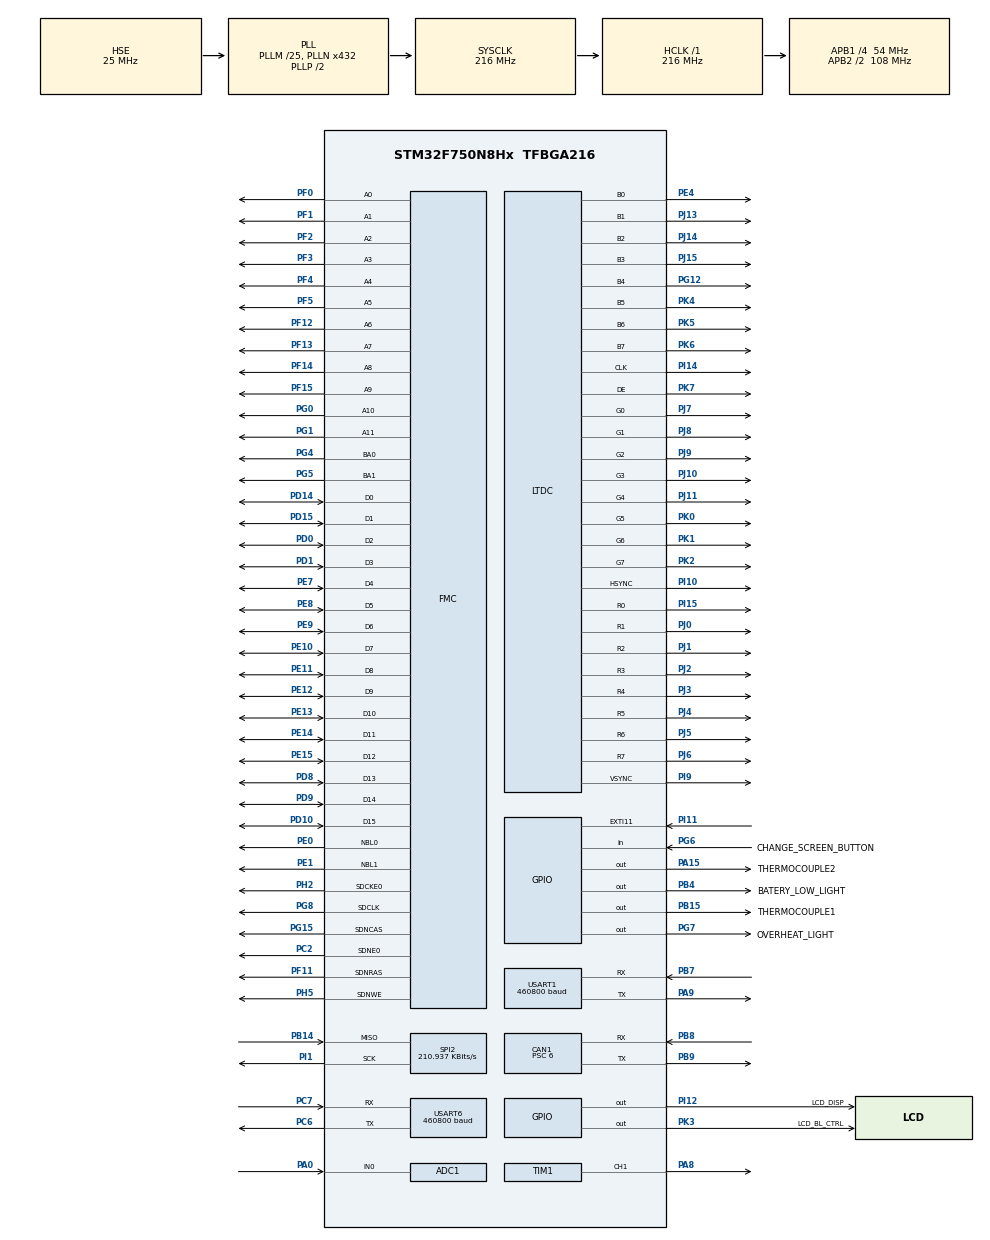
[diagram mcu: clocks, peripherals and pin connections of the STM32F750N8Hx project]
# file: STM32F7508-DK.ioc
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ADC1.Channel-0\#ChannelRegularConversion=ADC_CHANNEL_0
ADC1.NbrOfConversionFlag=1
ADC1.Rank-0\#ChannelRegularConversion=1
ADC1.SamplingTime-0\#ChannelRegularConversion=ADC_SAMPLETIME_3CYCLES
ADC1.master=1
CAN1.BS1=CAN_BS1_4TQ
CAN1.BS2=CAN_BS2_4TQ
CAN1.CalculateBaudRate=1000000
CAN1.CalculateTimeBit=1000
CAN1.CalculateTimeQuantum=111.11111111111111
CAN1.Prescaler=6
CORTEX_M7.ART_ACCLERATOR_ENABLE=1
CORTEX_M7.AccessPermission-Cortex_Memory_Protection_Unit_Region0_Settings=MPU_REGION_FULL_ACCESS
CORTEX_M7.AccessPermission-Cortex_Memory_Protection_Unit_Region1_Settings=MPU_REGION_NO_ACCESS
CORTEX_M7.AccessPermission-Cortex_Memory_Protection_Unit_Region2_Settings=MPU_REGION_FULL_ACCESS
CORTEX_M7.AccessPermission-Cortex_Memory_Protection_Unit_Region3_Settings=MPU_REGION_NO_ACCESS
CORTEX_M7.AccessPermission-Cortex_Memory_Protection_Unit_Region4_Settings=MPU_REGION_FULL_ACCESS
CORTEX_M7.AccessPermission-Cortex_Memory_Protection_Unit_Region5_Settings=MPU_REGION_FULL_ACCESS
CORTEX_M7.BaseAddress-Cortex_Memory_Protection_Unit_Region0_Settings=0x20000000
CORTEX_M7.BaseAddress-Cortex_Memory_Protection_Unit_Region1_Settings=0xC0000000
CORTEX_M7.BaseAddress-Cortex_Memory_Protection_Unit_Region2_Settings=0xC0000000
CORTEX_M7.BaseAddress-Cortex_Memory_Protection_Unit_Region3_Settings=0x90000000
CORTEX_M7.BaseAddress-Cortex_Memory_Protection_Unit_Region4_Settings=0x90000000
CORTEX_M7.BaseAddress-Cortex_Memory_Protection_Unit_Region5_Settings=0x90000000
CORTEX_M7.CPU_DCache=Enabled
CORTEX_M7.CPU_ICache=Enabled
CORTEX_M7.DisableExec-Cortex_Memory_Protection_Unit_Region0_Settings=MPU_INSTRUCTION_ACCESS_DISABLE
CORTEX_M7.DisableExec-Cortex_Memory_Protection_Unit_Region1_Settings=MPU_INSTRUCTION_ACCESS_DISABLE
CORTEX_M7.DisableExec-Cortex_Memory_Protection_Unit_Region2_Settings=MPU_INSTRUCTION_ACCESS_DISABLE
CORTEX_M7.DisableExec-Cortex_Memory_Protection_Unit_Region3_Settings=MPU_INSTRUCTION_ACCESS_DISABLE
CORTEX_M7.DisableExec-Cortex_Memory_Protection_Unit_Region4_Settings=MPU_INSTRUCTION_ACCESS_DISABLE
CORTEX_M7.Enable-Cortex_Memory_Protection_Unit_Region0_Settings=MPU_REGION_ENABLE
CORTEX_M7.Enable-Cortex_Memory_Protection_Unit_Region1_Settings=MPU_REGION_ENABLE
CORTEX_M7.Enable-Cortex_Memory_Protection_Unit_Region2_Settings=MPU_REGION_ENABLE
CORTEX_M7.Enable-Cortex_Memory_Protection_Unit_Region3_Settings=MPU_REGION_ENABLE
CORTEX_M7.Enable-Cortex_Memory_Protection_Unit_Region4_Settings=MPU_REGION_ENABLE
CORTEX_M7.Enable-Cortex_Memory_Protection_Unit_Region5_Settings=MPU_REGION_ENABLE
CORTEX_M7.IsBufferable-Cortex_Memory_Protection_Unit_Region0_Settings=MPU_ACCESS_BUFFERABLE
CORTEX_M7.IsBufferable-Cortex_Memory_Protection_Unit_Region1_Settings=MPU_ACCESS_NOT_BUFFERABLE
CORTEX_M7.IsBufferable-Cortex_Memory_Protection_Unit_Region2_Settings=MPU_ACCESS_BUFFERABLE
CORTEX_M7.IsBufferable-Cortex_Memory_Protection_Unit_Region3_Settings=MPU_ACCESS_NOT_BUFFERABLE
CORTEX_M7.IsBufferable-Cortex_Memory_Protection_Unit_Region4_Settings=MPU_ACCESS_BUFFERABLE
CORTEX_M7.IsBufferable-Cortex_Memory_Protection_Unit_Region5_Settings=MPU_ACCESS_BUFFERABLE
CORTEX_M7.IsCacheable-Cortex_Memory_Protection_Unit_Region0_Settings=MPU_ACCESS_CACHEABLE
CORTEX_M7.IsCacheable-Cortex_Memory_Protection_Unit_Region1_Settings=MPU_ACCESS_NOT_CACHEABLE
CORTEX_M7.IsCacheable-Cortex_Memory_Protection_Unit_Region2_Settings=MPU_ACCESS_CACHEABLE
CORTEX_M7.IsCacheable-Cortex_Memory_Protection_Unit_Region3_Settings=MPU_ACCESS_NOT_CACHEABLE
CORTEX_M7.IsCacheable-Cortex_Memory_Protection_Unit_Region4_Settings=MPU_ACCESS_CACHEABLE
CORTEX_M7.IsCacheable-Cortex_Memory_Protection_Unit_Region5_Settings=MPU_ACCESS_CACHEABLE
CORTEX_M7.MPU_Control=MPU_PRIVILEGED_DEFAULT
CORTEX_M7.PREFETCH_ENABLE=1
CORTEX_M7.Size-Cortex_Memory_Protection_Unit_Region0_Settings=MPU_REGION_SIZE_512KB
CORTEX_M7.Size-Cortex_Memory_Protection_Unit_Region1_Settings=MPU_REGION_SIZE_512MB
CORTEX_M7.Size-Cortex_Memory_Protection_Unit_Region2_Settings=MPU_REGION_SIZE_8MB
CORTEX_M7.Size-Cortex_Memory_Protection_Unit_Region3_Settings=MPU_REGION_SIZE_512MB
CORTEX_M7.Size-Cortex_Memory_Protection_Unit_Region4_Settings=MPU_REGION_SIZE_16MB
CORTEX_M7.Size-Cortex_Memory_Protection_Unit_Region5_Settings=MPU_REGION_SIZE_1MB
DMA2D.ColorMode=DMA2D_OUTPUT_ARGB8888
Dma.Request0=TIM1_CH1
Dma.Request1=SPI2_RX
Dma.Request2=USART6_RX
Dma.SPI2_RX.1.Direction=DMA_PERIPH_TO_MEMORY
Dma.SPI2_RX.1.FIFOMode=DMA_FIFOMODE_DISABLE
Dma.SPI2_RX.1.Instance=DMA1_Stream3
Dma.SPI2_RX.1.MemDataAlignment=DMA_MDATAALIGN_BYTE
Dma.SPI2_RX.1.MemInc=DMA_MINC_ENABLE
Dma.SPI2_RX.1.Mode=DMA_NORMAL
Dma.SPI2_RX.1.PeriphDataAlignment=DMA_PDATAALIGN_BYTE
Dma.SPI2_RX.1.PeriphInc=DMA_PINC_DISABLE
Dma.SPI2_RX.1.Priority=DMA_PRIORITY_LOW
Dma.TIM1_CH1.0.Direction=DMA_MEMORY_TO_PERIPH
Dma.TIM1_CH1.0.FIFOMode=DMA_FIFOMODE_DISABLE
Dma.TIM1_CH1.0.Instance=DMA2_Stream1
Dma.TIM1_CH1.0.MemDataAlignment=DMA_MDATAALIGN_HALFWORD
Dma.TIM1_CH1.0.MemInc=DMA_MINC_ENABLE
Dma.TIM1_CH1.0.Mode=DMA_NORMAL
Dma.TIM1_CH1.0.PeriphDataAlignment=DMA_PDATAALIGN_HALFWORD
Dma.TIM1_CH1.0.PeriphInc=DMA_PINC_DISABLE
Dma.TIM1_CH1.0.Priority=DMA_PRIORITY_LOW
Dma.USART6_RX.2.Direction=DMA_PERIPH_TO_MEMORY
Dma.USART6_RX.2.FIFOMode=DMA_FIFOMODE_DISABLE
Dma.USART6_RX.2.Instance=DMA2_Stream2
Dma.USART6_RX.2.MemDataAlignment=DMA_MDATAALIGN_BYTE
Dma.USART6_RX.2.MemInc=DMA_MINC_ENABLE
Dma.USART6_RX.2.Mode=DMA_NORMAL
Dma.USART6_RX.2.PeriphDataAlignment=DMA_PDATAALIGN_BYTE
Dma.USART6_RX.2.PeriphInc=DMA_PINC_DISABLE
Dma.USART6_RX.2.Priority=DMA_PRIORITY_LOW
FREERTOS.INCLUDE_eTaskGetState=1
FREERTOS.INCLUDE_pcTaskGetTaskName=0
FREERTOS.INCLUDE_uxTaskGetStackHighWaterMark=1
FREERTOS.INCLUDE_vTaskCleanUpResources=0
FREERTOS.INCLUDE_vTaskDelayUntil=1
FREERTOS.INCLUDE_xQueueGetMutexHolder=1
FREERTOS.INCLUDE_xSemaphoreGetMutexHolder=1
FREERTOS.INCLUDE_xTimerPendFunctionCall=1
FREERTOS.MEMORY_ALLOCATION=2
FREERTOS.Queues01=buttonQueue,4,uint8_t,0,Dynamic,NULL,NULL;shifterQueue,8,uint8_t,0,Dynamic,NULL,NULL
FREERTOS.Tasks01=defaultTask,24,128,StartDefaultTask,Default,NULL,Dynamic,NULL,NULL;TouchGFXTask,24,8192,TouchGFX_Task,As external,NULL,Dynamic,NULL,NULL;rpmTask,8,128,StartRPMTask,Default,NULL,Dynamic,NULL,NULL;egtTask,8,128,StartEGTTask,Default,NULL,Dynamic,NULL,NULL;shifterTask,8,128,StartShifterTask,Default,NULL,Dynamic,NULL,NULL;gpsTask,8,128,StartGPSTask,Default,NULL,Dynamic,NULL,NULL;debounceTask,8,128,StartDebounce,Default,NULL,Dynamic,NULL,NULL
FREERTOS.configTOTAL_HEAP_SIZE=65536
FREERTOS.configUSE_APPLICATION_TASK_TAG=1
FREERTOS.configUSE_COUNTING_SEMAPHORES=1
FREERTOS.configUSE_IDLE_HOOK=1
FREERTOS.configUSE_RECURSIVE_MUTEXES=1
FREERTOS.configUSE_TIMERS=1
FREERTOS.configUSE_TRACE_FACILITY=1
LTDC.ActiveH=272
LTDC.ActiveW=480
LTDC.Alpha_L0=255
LTDC.HBP=13
LTDC.HFP=32
LTDC.HSync=41
LTDC.ImageHeight_L0=272
LTDC.ImageWidth_L0=480
LTDC.Layers=0
LTDC.PixelFormat_L0=LTDC_PIXEL_FORMAT_RGB565
LTDC.VSync=10
LTDC.WindowX1_L0=480
LTDC.WindowY1_L0=272
Mcu.Family=STM32F7
Mcu.Name=STM32F750N8Hx
Mcu.Package=TFBGA216
NVIC.CAN1_RX0_IRQn=true\:5\:0\:false\:false\:true\:true\:true\:true\:true
NVIC.CAN1_TX_IRQn=true\:5\:0\:false\:false\:true\:true\:true\:true\:true
NVIC.DMA1_Stream3_IRQn=true\:5\:0\:false\:false\:true\:true\:false\:true\:true
NVIC.DMA2D_IRQn=true\:5\:0\:true\:false\:true\:false\:true\:true\:true
NVIC.DMA2_Stream1_IRQn=true\:5\:0\:false\:false\:true\:true\:false\:true\:true
NVIC.DMA2_Stream2_IRQn=true\:5\:0\:false\:false\:true\:true\:false\:true\:true
NVIC.EXTI15_10_IRQn=true\:5\:0\:false\:false\:true\:true\:true\:true\:true
NVIC.LTDC_IRQn=true\:5\:0\:true\:false\:true\:false\:true\:true\:true
NVIC.PriorityGroup=NVIC_PRIORITYGROUP_4
NVIC.TIM2_IRQn=true\:5\:0\:false\:false\:true\:true\:true\:true\:true
NVIC.TIM6_DAC_IRQn=true\:0\:0\:false\:false\:true\:false\:false\:true\:true
NVIC.TimeBase=TIM6_DAC_IRQn
NVIC.TimeBaseIP=TIM6
NVIC.USART6_IRQn=true\:5\:0\:false\:false\:true\:true\:true\:true\:true
PA0/WKUP.Signal=ADCx_IN0
PA15.GPIO_Label=THERMOCOUPLE2
PA15.Signal=GPIO_Output
PA8.Signal=S_TIM1_CH1
PA9.Mode=Asynchronous
PA9.Signal=USART1_TX
PB14.Mode=RX_Only_Simplex_Unidirect_Master
PB14.Signal=SPI2_MISO
PB15.GPIO_Label=THERMOCOUPLE1
PB15.Signal=GPIO_Output
PB4.GPIO_Label=BATERY_LOW_LIGHT
PB4.Signal=GPIO_Output
PB7.Mode=Asynchronous
PB7.Signal=USART1_RX
PB8.Mode=CAN_Activate
PB8.Signal=CAN1_RX
PB9.Mode=CAN_Activate
PB9.Signal=CAN1_TX
PC2.Mode=SdramChipSelect1_1
PC2.Signal=FMC_SDNE0
PC6.Mode=Asynchronous
PC6.Signal=USART6_TX
PC7.Mode=Asynchronous
PC7.Signal=USART6_RX
PD0.Signal=FMC_D2_DA2
PD1.Signal=FMC_D3_DA3
PD10.Signal=FMC_D15_DA15
PD14.Signal=FMC_D0_DA0
PD15.Signal=FMC_D1_DA1
PD8.Signal=FMC_D13_DA13
PD9.Signal=FMC_D14_DA14
PE0.Signal=FMC_NBL0
PE1.Signal=FMC_NBL1
PE10.Signal=FMC_D7_DA7
PE11.Signal=FMC_D8_DA8
PE12.Signal=FMC_D9_DA9
PE13.Signal=FMC_D10_DA10
PE14.Signal=FMC_D11_DA11
PE15.Signal=FMC_D12_DA12
PE4.GPIO_Speed=GPIO_SPEED_FREQ_HIGH
PE4.Mode=RGB888
PE4.Signal=LTDC_B0
PE7.Signal=FMC_D4_DA4
PE8.Signal=FMC_D5_DA5
PE9.Signal=FMC_D6_DA6
PF0.Signal=FMC_A0
PF1.Signal=FMC_A1
PF11.Signal=FMC_SDNRAS
PF12.Signal=FMC_A6
PF13.Signal=FMC_A7
PF14.Signal=FMC_A8
PF15.Signal=FMC_A9
PF2.Signal=FMC_A2
PF3.Signal=FMC_A3
PF4.Signal=FMC_A4
PF5.Signal=FMC_A5
PG0.Signal=FMC_A10
PG1.Signal=FMC_A11
PG12.GPIO_Speed=GPIO_SPEED_FREQ_HIGH
PG12.Mode=RGB888
PG12.Signal=LTDC_B4
PG15.Signal=FMC_SDNCAS
PG4.Signal=FMC_A14_BA0
PG5.Signal=FMC_A15_BA1
PG6.GPIO_Label=CHANGE_SCREEN_BUTTON
PG6.GPIO_PuPd=GPIO_PULLUP
PG6.Signal=GPIO_Input
PG7.GPIO_Label=OVERHEAT_LIGHT
PG7.Signal=GPIO_Output
PG8.Signal=FMC_SDCLK
PH0/OSC_IN.Mode=HSE-External-Oscillator
PH0/OSC_IN.Signal=RCC_OSC_IN
PH1/OSC_OUT.Mode=HSE-External-Oscillator
PH1/OSC_OUT.Signal=RCC_OSC_OUT
PH2.Mode=SdramChipSelect1_1
PH2.Signal=FMC_SDCKE0
PH5.Signal=FMC_SDNWE
PI1.Mode=RX_Only_Simplex_Unidirect_Master
PI1.Signal=SPI2_SCK
PI10.GPIO_Speed=GPIO_SPEED_FREQ_HIGH
PI10.Mode=RGB888
PI10.Signal=LTDC_HSYNC
PI11.GPIO_PuPd=GPIO_PULLDOWN
PI11.Signal=GPXTI11
PI12.GPIO_Label=LCD_DISP
PI12.Signal=GPIO_Output
PI14.GPIO_Speed=GPIO_SPEED_FREQ_HIGH
PI14.Mode=RGB888
PI14.Signal=LTDC_CLK
PI15.GPIO_Speed=GPIO_SPEED_FREQ_HIGH
PI15.Mode=RGB888
PI15.Signal=LTDC_R0
PI9.GPIO_Speed=GPIO_SPEED_FREQ_HIGH
PI9.Mode=RGB888
PI9.Signal=LTDC_VSYNC
PJ0.GPIO_Speed=GPIO_SPEED_FREQ_HIGH
PJ0.Mode=RGB888
PJ0.Signal=LTDC_R1
PJ1.GPIO_Speed=GPIO_SPEED_FREQ_HIGH
PJ1.Mode=RGB888
PJ1.Signal=LTDC_R2
PJ10.GPIO_Speed=GPIO_SPEED_FREQ_HIGH
PJ10.Mode=RGB888
PJ10.Signal=LTDC_G3
PJ11.GPIO_Speed=GPIO_SPEED_FREQ_HIGH
PJ11.Mode=RGB888
PJ11.Signal=LTDC_G4
PJ13.GPIO_Speed=GPIO_SPEED_FREQ_HIGH
PJ13.Mode=RGB888
PJ13.Signal=LTDC_B1
PJ14.GPIO_Speed=GPIO_SPEED_FREQ_HIGH
PJ14.Mode=RGB888
PJ14.Signal=LTDC_B2
PJ15.GPIO_Speed=GPIO_SPEED_FREQ_HIGH
PJ15.Mode=RGB888
PJ15.Signal=LTDC_B3
PJ2.GPIO_Speed=GPIO_SPEED_FREQ_HIGH
PJ2.Mode=RGB888
PJ2.Signal=LTDC_R3
PJ3.GPIO_Speed=GPIO_SPEED_FREQ_HIGH
PJ3.Mode=RGB888
PJ3.Signal=LTDC_R4
PJ4.GPIO_Speed=GPIO_SPEED_FREQ_HIGH
PJ4.Mode=RGB888
PJ4.Signal=LTDC_R5
PJ5.GPIO_Speed=GPIO_SPEED_FREQ_HIGH
PJ5.Mode=RGB888
PJ5.Signal=LTDC_R6
PJ6.GPIO_Speed=GPIO_SPEED_FREQ_HIGH
PJ6.Mode=RGB888
PJ6.Signal=LTDC_R7
PJ7.GPIO_Speed=GPIO_SPEED_FREQ_HIGH
PJ7.Mode=RGB888
PJ7.Signal=LTDC_G0
PJ8.GPIO_Speed=GPIO_SPEED_FREQ_HIGH
PJ8.Mode=RGB888
PJ8.Signal=LTDC_G1
PJ9.GPIO_Speed=GPIO_SPEED_FREQ_HIGH
PJ9.Mode=RGB888
PJ9.Signal=LTDC_G2
PK0.GPIO_Speed=GPIO_SPEED_FREQ_HIGH
PK0.Mode=RGB888
PK0.Signal=LTDC_G5
PK1.GPIO_Speed=GPIO_SPEED_FREQ_HIGH
PK1.Mode=RGB888
PK1.Signal=LTDC_G6
PK2.GPIO_Speed=GPIO_SPEED_FREQ_HIGH
PK2.Mode=RGB888
PK2.Signal=LTDC_G7
PK3.GPIO_Label=LCD_BL_CTRL
PK3.Signal=GPIO_Output
PK4.GPIO_Speed=GPIO_SPEED_FREQ_HIGH
PK4.Mode=RGB888
PK4.Signal=LTDC_B5
PK5.GPIO_Speed=GPIO_SPEED_FREQ_HIGH
PK5.Mode=RGB888
PK5.Signal=LTDC_B6
PK6.GPIO_Speed=GPIO_SPEED_FREQ_HIGH
PK6.Mode=RGB888
PK6.Signal=LTDC_B7
PK7.GPIO_Speed=GPIO_SPEED_FREQ_HIGH
PK7.Mode=RGB888
PK7.Signal=LTDC_DE
ProjectManager.HeapSize=0x1000
ProjectManager.StackSize=0x1000
ProjectManager.TargetToolchain=STM32CubeIDE
RCC.AHBFreq_Value=216000000
RCC.APB1CLKDivider=RCC_HCLK_DIV4
RCC.APB1Freq_Value=54000000
RCC.APB1TimFreq_Value=108000000
RCC.APB2CLKDivider=RCC_HCLK_DIV2
RCC.APB2Freq_Value=108000000
RCC.APB2TimFreq_Value=216000000
RCC.CortexFreq_Value=216000000
RCC.HCLKFreq_Value=216000000
RCC.HSE_VALUE=25000000
RCC.HSI_VALUE=16000000
RCC.LSE_VALUE=32768
RCC.PLLM=25
RCC.PLLN=432
RCC.PLLSAIN=100
RCC.PLLSourceVirtual=RCC_PLLSOURCE_HSE
RCC.SYSCLKFreq_VALUE=216000000
RCC.SYSCLKSource=RCC_SYSCLKSOURCE_PLLCLK
RCC.USBFreq_Value=216000000
RCC.VCOOutputFreq_Value=432000000
SH.ADCx_IN0.0=ADC1_IN0,IN0
SH.FMC_A0.0=FMC_A0,12b-sda1
SH.FMC_A1.0=FMC_A1,12b-sda1
SH.FMC_A10.0=FMC_A10,12b-sda1
SH.FMC_A11.0=FMC_A11,12b-sda1
SH.FMC_A14_BA0.0=FMC_BA0,FourSdramBanks1
SH.FMC_A15_BA1.0=FMC_BA1,FourSdramBanks1
SH.FMC_A2.0=FMC_A2,12b-sda1
SH.FMC_A3.0=FMC_A3,12b-sda1
SH.FMC_A4.0=FMC_A4,12b-sda1
SH.FMC_A5.0=FMC_A5,12b-sda1
SH.FMC_A6.0=FMC_A6,12b-sda1
SH.FMC_A7.0=FMC_A7,12b-sda1
SH.FMC_A8.0=FMC_A8,12b-sda1
SH.FMC_A9.0=FMC_A9,12b-sda1
SH.FMC_D0_DA0.0=FMC_D0,sd-16b-d1
SH.FMC_D10_DA10.0=FMC_D10,sd-16b-d1
SH.FMC_D11_DA11.0=FMC_D11,sd-16b-d1
SH.FMC_D12_DA12.0=FMC_D12,sd-16b-d1
SH.FMC_D13_DA13.0=FMC_D13,sd-16b-d1
SH.FMC_D14_DA14.0=FMC_D14,sd-16b-d1
SH.FMC_D15_DA15.0=FMC_D15,sd-16b-d1
SH.FMC_D1_DA1.0=FMC_D1,sd-16b-d1
SH.FMC_D2_DA2.0=FMC_D2,sd-16b-d1
SH.FMC_D3_DA3.0=FMC_D3,sd-16b-d1
SH.FMC_D4_DA4.0=FMC_D4,sd-16b-d1
SH.FMC_D5_DA5.0=FMC_D5,sd-16b-d1
SH.FMC_D6_DA6.0=FMC_D6,sd-16b-d1
SH.FMC_D7_DA7.0=FMC_D7,sd-16b-d1
SH.FMC_D8_DA8.0=FMC_D8,sd-16b-d1
SH.FMC_D9_DA9.0=FMC_D9,sd-16b-d1
SH.FMC_NBL0.0=FMC_NBL0,Sd2ByteEnable1
SH.FMC_NBL1.0=FMC_NBL1,Sd2ByteEnable1
SH.FMC_SDCLK.0=FMC_SDCLK,12b-sda1
SH.FMC_SDNCAS.0=FMC_SDNCAS,12b-sda1
SH.FMC_SDNRAS.0=FMC_SDNRAS,12b-sda1
SH.FMC_SDNWE.0=FMC_SDNWE,12b-sda1
SH.S_TIM1_CH1.0=TIM1_CH1,PWM Generation1 CH1
SPI2.BaudRatePrescaler=SPI_BAUDRATEPRESCALER_256
SPI2.CalculateBaudRate=210.937 KBits/s
SPI2.DataSize=SPI_DATASIZE_8BIT
SPI2.Direction=SPI_DIRECTION_2LINES_RXONLY
SPI2.Mode=SPI_MODE_MASTER
SPI2.VirtualType=VM_MASTER
STMicroelectronics.X-CUBE-TOUCHGFX.4.23.0.ApplicationCcGraphicsJjApplication=TouchGFXOoGenerator
STMicroelectronics.X-CUBE-TOUCHGFX.4.23.0.tgfx_address1=0xC0000000
STMicroelectronics.X-CUBE-TOUCHGFX.4.23.0.tgfx_address2=0xC003FC00
STMicroelectronics.X-CUBE-TOUCHGFX.4.23.0.tgfx_buffering_strategy=Double
STMicroelectronics.X-CUBE-TOUCHGFX.4.23.0.tgfx_display_interface=disp_ltdc
STMicroelectronics.X-CUBE-TOUCHGFX.4.23.0.tgfx_hardware_accelerator=dma_2d
STMicroelectronics.X-CUBE-TOUCHGFX.4.23.0.tgfx_location=By Address
STMicroelectronics.X-CUBE-TOUCHGFX.4.23.0.tgfx_vector_rendering=Enabled
STMicroelectronics.X-CUBE-TOUCHGFX.4.23.0.tgfx_vsync=vsync_ltdc
TIM1.AutoReloadPreload=TIM_AUTORELOAD_PRELOAD_ENABLE
TIM1.Channel-PWM\ Generation1\ CH1=TIM_CHANNEL_1
TIM1.Period=270
TIM2.AutoReloadPreload=TIM_AUTORELOAD_PRELOAD_ENABLE
TIM2.Period=30000
TIM2.Prescaler=1000
USART1.BaudRate=460800
USART1.VirtualMode-Asynchronous=VM_ASYNC
USART6.BaudRate=460800
USART6.VirtualMode-Asynchronous=VM_ASYNC
VP_CRC_VS_CRC.Mode=CRC_Activate
VP_DMA2D_VS_DMA2D.Mode=DMA2D_Activate
VP_FREERTOS_VS_CMSIS_V2.Mode=CMSIS_V2
VP_STMicroelectronics.X-CUBE-TOUCHGFX_VS_GraphicsJjApplication_4.23.0.Mode=GraphicsJjApplication
VP_SYS_VS_tim6.Mode=TIM6
VP_TIM1_VS_ClockSourceINT.Mode=Internal
VP_TIM2_VS_ClockSourceINT.Mode=Internal
board=custom

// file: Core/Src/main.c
/* USER CODE BEGIN Header */
/**
  ******************************************************************************
  * @file           : main.c
  * @brief          : Main program body
  ******************************************************************************
  * @attention
  *
  * <h2><center>&copy; Copyright (c) 2020 STMicroelectronics.
  * All rights reserved.</center></h2>
  *
  * This software component is licensed by ST under Ultimate Liberty license
  * SLA0044, the "License"; You may not use this file except in compliance with
  * the License. You may obtain a copy of the License at:
  *                             www.st.com/SLA0044
  *
  ******************************************************************************
  */
/* USER CODE END Header */
#include "main.h"
#include "cmsis_os.h"
#include "adc.h"
#include "can.h"
#include "crc.h"
#include "dma.h"
#include "dma2d.h"
#include "ltdc.h"
#include "spi.h"
#include "tim.h"
#include "usart.h"
#include "gpio.h"
#include "fmc.h"
#include "app_touchgfx.h"

/* USER CODE BEGIN Includes */
#include "stm32f7508_discovery_sdram.h"
/* USER CODE END Includes */

void SystemClock_Config(void);
static void MPU_Config(void);
void MX_FREERTOS_Init(void);

int main(void)
{

  /* MPU Configuration--------------------------------------------------------*/
  MPU_Config();

  /* Enable I-Cache---------------------------------------------------------*/
  SCB_EnableICache();

  /* Enable D-Cache---------------------------------------------------------*/
  SCB_EnableDCache();

  /* MCU Configuration--------------------------------------------------------*/

  /* Reset of all peripherals, Initializes the Flash interface and the Systick. */
  HAL_Init();

  /* Configure the system clock */
  SystemClock_Config();

  /* Initialize all configured peripherals */
  MX_GPIO_Init();
  MX_DMA_Init();
  MX_DMA2D_Init();
  MX_FMC_Init();
  MX_LTDC_Init();
  MX_USART1_UART_Init();
  MX_CAN1_Init();
  MX_TIM1_Init();
  MX_CRC_Init();
  MX_TIM2_Init();
  MX_SPI2_Init();
  MX_ADC1_Init();
  MX_USART6_UART_Init();
  MX_TouchGFX_Init();
  /* Call PreOsInit function */
  MX_TouchGFX_PreOSInit();
  /* USER CODE BEGIN 2 */
  HAL_CAN_Start(&hcan1);
  HAL_CAN_ActivateNotification(&hcan1, CAN_IT_RX_FIFO0_MSG_PENDING);
  HAL_CAN_ActivateNotification(&hcan1, CAN_IT_TX_MAILBOX_EMPTY);

  /* USER CODE END 2 */

  /* Init scheduler */
  osKernelInitialize();  /* Call init function for freertos objects (in freertos.c) */
  MX_FREERTOS_Init();

  /* Start scheduler */
  osKernelStart();
  /* We should never get here as control is now taken by the scheduler */
  /* Infinite loop */
  while (1)
  {

  }
}

void SystemClock_Config(void)
{
  RCC_OscInitTypeDef RCC_OscInitStruct = {0};
  RCC_ClkInitTypeDef RCC_ClkInitStruct = {0};

  /** Configure the main internal regulator output voltage
  */
  __HAL_RCC_PWR_CLK_ENABLE();
  __HAL_PWR_VOLTAGESCALING_CONFIG(PWR_REGULATOR_VOLTAGE_SCALE1);

  /** Initializes the RCC Oscillators according to the specified parameters
  * in the RCC_OscInitTypeDef structure.
  */
  RCC_OscInitStruct.OscillatorType = RCC_OSCILLATORTYPE_HSE;
  RCC_OscInitStruct.HSEState = RCC_HSE_ON;
  RCC_OscInitStruct.PLL.PLLState = RCC_PLL_ON;
  RCC_OscInitStruct.PLL.PLLSource = RCC_PLLSOURCE_HSE;
  RCC_OscInitStruct.PLL.PLLM = 25;
  RCC_OscInitStruct.PLL.PLLN = 432;
  RCC_OscInitStruct.PLL.PLLP = RCC_PLLP_DIV2;
  RCC_OscInitStruct.PLL.PLLQ = 2;
  if (HAL_RCC_OscConfig(&RCC_OscInitStruct) != HAL_OK)
  {
    Error_Handler();
  }

  /** Activate the Over-Drive mode
  */
  if (HAL_PWREx_EnableOverDrive() != HAL_OK)
  {
    Error_Handler();
  }

  /** Initializes the CPU, AHB and APB buses clocks
  */
  RCC_ClkInitStruct.ClockType = RCC_CLOCKTYPE_HCLK|RCC_CLOCKTYPE_SYSCLK
                              |RCC_CLOCKTYPE_PCLK1|RCC_CLOCKTYPE_PCLK2;
  RCC_ClkInitStruct.SYSCLKSource = RCC_SYSCLKSOURCE_PLLCLK;
  RCC_ClkInitStruct.AHBCLKDivider = RCC_SYSCLK_DIV1;
  RCC_ClkInitStruct.APB1CLKDivider = RCC_HCLK_DIV4;
  RCC_ClkInitStruct.APB2CLKDivider = RCC_HCLK_DIV2;

  if (HAL_RCC_ClockConfig(&RCC_ClkInitStruct, FLASH_LATENCY_7) != HAL_OK)
  {
    Error_Handler();
  }
}

/* MPU Configuration */

void MPU_Config(void)
{
  MPU_Region_InitTypeDef MPU_InitStruct = {0};

  /* Disables the MPU */
  HAL_MPU_Disable();

  /** Initializes and configures the Region and the memory to be protected
  */
  MPU_InitStruct.Enable = MPU_REGION_ENABLE;
  MPU_InitStruct.Number = MPU_REGION_NUMBER0;
  MPU_InitStruct.BaseAddress = 0x20000000;
  MPU_InitStruct.Size = MPU_REGION_SIZE_512KB;
  MPU_InitStruct.SubRegionDisable = 0x0;
  MPU_InitStruct.TypeExtField = MPU_TEX_LEVEL0;
  MPU_InitStruct.AccessPermission = MPU_REGION_FULL_ACCESS;
  MPU_InitStruct.DisableExec = MPU_INSTRUCTION_ACCESS_DISABLE;
  MPU_InitStruct.IsShareable = MPU_ACCESS_NOT_SHAREABLE;
  MPU_InitStruct.IsCacheable = MPU_ACCESS_CACHEABLE;
  MPU_InitStruct.IsBufferable = MPU_ACCESS_BUFFERABLE;

  HAL_MPU_ConfigRegion(&MPU_InitStruct);

  /** Initializes and configures the Region and the memory to be protected
  */
  MPU_InitStruct.Number = MPU_REGION_NUMBER1;
  MPU_InitStruct.BaseAddress = 0xC0000000;
  MPU_InitStruct.Size = MPU_REGION_SIZE_512MB;
  MPU_InitStruct.AccessPermission = MPU_REGION_NO_ACCESS;
  MPU_InitStruct.IsCacheable = MPU_ACCESS_NOT_CACHEABLE;
  MPU_InitStruct.IsBufferable = MPU_ACCESS_NOT_BUFFERABLE;

  HAL_MPU_ConfigRegion(&MPU_InitStruct);

  /** Initializes and configures the Region and the memory to be protected
  */
  MPU_InitStruct.Number = MPU_REGION_NUMBER2;
  MPU_InitStruct.Size = MPU_REGION_SIZE_8MB;
  MPU_InitStruct.AccessPermission = MPU_REGION_FULL_ACCESS;
  MPU_InitStruct.IsCacheable = MPU_ACCESS_CACHEABLE;
  MPU_InitStruct.IsBufferable = MPU_ACCESS_BUFFERABLE;

  HAL_MPU_ConfigRegion(&MPU_InitStruct);

  /** Initializes and configures the Region and the memory to be protected
  */
  MPU_InitStruct.Number = MPU_REGION_NUMBER3;
  MPU_InitStruct.BaseAddress = 0x90000000;
  MPU_InitStruct.Size = MPU_REGION_SIZE_512MB;
  MPU_InitStruct.AccessPermission = MPU_REGION_NO_ACCESS;
  MPU_InitStruct.IsCacheable = MPU_ACCESS_NOT_CACHEABLE;
  MPU_InitStruct.IsBufferable = MPU_ACCESS_NOT_BUFFERABLE;

  HAL_MPU_ConfigRegion(&MPU_InitStruct);

  /** Initializes and configures the Region and the memory to be protected
  */
  MPU_InitStruct.Number = MPU_REGION_NUMBER4;
  MPU_InitStruct.Size = MPU_REGION_SIZE_16MB;
  MPU_InitStruct.AccessPermission = MPU_REGION_FULL_ACCESS;
  MPU_InitStruct.IsCacheable = MPU_ACCESS_CACHEABLE;
  MPU_InitStruct.IsBufferable = MPU_ACCESS_BUFFERABLE;

  HAL_MPU_ConfigRegion(&MPU_InitStruct);

  /** Initializes and configures the Region and the memory to be protected
  */
  MPU_InitStruct.Number = MPU_REGION_NUMBER5;
  MPU_InitStruct.Size = MPU_REGION_SIZE_1MB;
  MPU_InitStruct.DisableExec = MPU_INSTRUCTION_ACCESS_ENABLE;

  HAL_MPU_ConfigRegion(&MPU_InitStruct);
  /* Enables the MPU */
  HAL_MPU_Enable(MPU_PRIVILEGED_DEFAULT);

}

void HAL_TIM_PeriodElapsedCallback(TIM_HandleTypeDef *htim)
{
  if (htim->Instance == TIM6) {
    HAL_IncTick();
  }
}

void Error_Handler(void)
{
  /* USER CODE BEGIN Error_Handler_Debug */
  /* User can add his own implementation to report the HAL error return state */
  while(1);
  /* USER CODE END Error_Handler_Debug */
}

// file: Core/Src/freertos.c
/* USER CODE BEGIN Header */
/**
  ******************************************************************************
  * File Name          : freertos.c
  * Description        : Code for freertos applications
  ******************************************************************************
  * @attention
  *
  * <h2><center>&copy; Copyright (c) 2020 STMicroelectronics.
  * All rights reserved.</center></h2>
  *
  * This software component is licensed by ST under Ultimate Liberty license
  * SLA0044, the "License"; You may not use this file except in compliance with
  * the License. You may obtain a copy of the License at:
  *                             www.st.com/SLA0044
  *
  ******************************************************************************
  */
/* USER CODE END Header */

#include "FreeRTOS.h"
#include "task.h"
#include "main.h"
#include "cmsis_os.h"

/* USER CODE BEGIN Includes */
#include "can.h"
#include "gpio.h"
#include "spi.h"
#include "adc.h"
#include "usart.h"
#include "gps.h"
/* USER CODE END Includes */

/* USER CODE BEGIN PD */
#define ADCSHIFTUP 3000
#define ADCSHIFTDOWN 1700
/* USER CODE END PD */

/* USER CODE BEGIN Variables */
uint32_t TxMailbox;
uint32_t lapTimeMilliSeconds;
gpsData_t *gpsData_r;
extern uint16_t rpm;
extern CAN_TxHeaderTypeDef TxHeader;
extern uint16_t egt3;
extern uint16_t egt4;
extern uint8_t gpsData[UARTBUFFERLENGTH];
extern uint8_t neutralSwitch;

/* USER CODE END Variables */
/* Definitions for defaultTask */
osThreadId_t defaultTaskHandle;
const osThreadAttr_t defaultTask_attributes = {
  .name = "defaultTask",
  .stack_size = 256 * 4,
  .priority = (osPriority_t) osPriorityNormal,
};
/* Definitions for TouchGFXTask */
osThreadId_t TouchGFXTaskHandle;
const osThreadAttr_t TouchGFXTask_attributes = {
  .name = "TouchGFXTask",
  .stack_size = 8192 * 4,
  .priority = (osPriority_t) osPriorityNormal,
};
/* Definitions for rpmTask */
osThreadId_t rpmTaskHandle;
const osThreadAttr_t rpmTask_attributes = {
  .name = "rpmTask",
  .stack_size = 256 * 4,
  .priority = (osPriority_t) osPriorityLow,
};
/* Definitions for egtTask */
osThreadId_t egtTaskHandle;
const osThreadAttr_t egtTask_attributes = {
  .name = "egtTask",
  .stack_size = 256 * 4,
  .priority = (osPriority_t) osPriorityLow,
};
/* Definitions for shifterTask */
osThreadId_t shifterTaskHandle;
const osThreadAttr_t shifterTask_attributes = {
  .name = "shifterTask",
  .stack_size = 256 * 4,
  .priority = (osPriority_t) osPriorityLow,
};
/* Definitions for gpsTask */
osThreadId_t gpsTaskHandle;
const osThreadAttr_t gpsTask_attributes = {
  .name = "gpsTask",
  .stack_size = 256 * 4,
  .priority = (osPriority_t) osPriorityNormal,
};
/* Definitions for debounceTask */
osThreadId_t debounceTaskHandle;
const osThreadAttr_t debounceTask_attributes = {
  .name = "debounceTask",
  .stack_size = 256 * 4,
  .priority = (osPriority_t) osPriorityLow,
};
/* Definitions for buttonQueue */
osMessageQueueId_t buttonQueueHandle;
const osMessageQueueAttr_t buttonQueue_attributes = {
  .name = "buttonQueue"
};
/* Definitions for shifterQueue */
osMessageQueueId_t shifterQueueHandle;
const osMessageQueueAttr_t shifterQueue_attributes = {
  .name = "shifterQueue"
};
/* Definitions for lapTimer */
osTimerId_t lapTimerHandle;
const osTimerAttr_t lapTimer_attributes = {
  .name = "lapTimer"
};

/* USER CODE BEGIN FunctionPrototypes */
extern portBASE_TYPE IdleTaskHook(void* p);
/* USER CODE END FunctionPrototypes */

void StartDefaultTask(void *argument);
extern void TouchGFX_Task(void *argument);
void StartRPMTask(void *argument);
void StartEGTTask(void *argument);
void StartShifterTask(void *argument);
void StartGPSTask(void *argument);
void StartDebounce(void *argument);
void lapTimerCallback(void *argument);

void MX_FREERTOS_Init(void); /* (MISRA C 2004 rule 8.1) */

/* Hook prototypes */
void vApplicationIdleHook(void);

/* USER CODE BEGIN 2 */
void vApplicationIdleHook( void )
{
   /* vApplicationIdleHook() will only be called if configUSE_IDLE_HOOK is set
   to 1 in FreeRTOSConfig.h. It will be called on each iteration of the idle
   task. It is essential that code added to this hook function never attempts
   to block in any way (for example, call xQueueReceive() with a block time
   specified, or call vTaskDelay()). If the application makes use of the
   vTaskDelete() API function (as this demo application does) then it is also
   important that vApplicationIdleHook() is permitted to return to its calling
   function, because it is the responsibility of the idle task to clean up
   memory allocated by the kernel to any task that has since been deleted. */
   vTaskSetApplicationTaskTag(NULL, IdleTaskHook);
}
/* USER CODE END 2 */

void MX_FREERTOS_Init(void) {

  /* Create the timer(s) */
  /* creation of lapTimer */
  lapTimerHandle = osTimerNew(lapTimerCallback, osTimerPeriodic, NULL, &lapTimer_attributes);

  /* Create the queue(s) */
  /* creation of buttonQueue */
  buttonQueueHandle = osMessageQueueNew (4, sizeof(uint8_t), &buttonQueue_attributes);

  /* creation of shifterQueue */
  shifterQueueHandle = osMessageQueueNew (8, sizeof(uint8_t), &shifterQueue_attributes);

  /* Create the thread(s) */
  /* creation of defaultTask */
  defaultTaskHandle = osThreadNew(StartDefaultTask, NULL, &defaultTask_attributes);

  /* creation of TouchGFXTask */
  TouchGFXTaskHandle = osThreadNew(TouchGFX_Task, NULL, &TouchGFXTask_attributes);

  /* creation of rpmTask */
  rpmTaskHandle = osThreadNew(StartRPMTask, NULL, &rpmTask_attributes);

  /* creation of egtTask */
  egtTaskHandle = osThreadNew(StartEGTTask, NULL, &egtTask_attributes);

  /* creation of shifterTask */
  shifterTaskHandle = osThreadNew(StartShifterTask, NULL, &shifterTask_attributes);

  /* creation of gpsTask */
  gpsTaskHandle = osThreadNew(StartGPSTask, NULL, &gpsTask_attributes);

  /* creation of debounceTask */
  debounceTaskHandle = osThreadNew(StartDebounce, NULL, &debounceTask_attributes);

}

void StartDefaultTask(void *argument)
{
  /* USER CODE BEGIN StartDefaultTask */
  /* Infinite loop */
	for(;;){
//		SendDriverScreenData();
		osDelay(100);
	}
  /* USER CODE END StartDefaultTask */
}

void StartRPMTask(void *argument)
{
  /* USER CODE BEGIN StartRPMTask */

  /* Infinite loop */
	for(;;){
		if(neutralSwitch){
			SetRPMNeutral();
		}else{
			SetRPMLights(rpm);
		}
		osDelay(100);
	}
  /* USER CODE END StartRPMTask */
}

void StartEGTTask(void *argument)
{
  /* USER CODE BEGIN StartEGTTask */

	uint8_t data[8] = { 0, 0, 0, 0, 0, 0, 0, 0 };
  /* Infinite loop */
	for(;;){
		egt3 = ReadTemp(egt1Pin);
		egt4 = ReadTemp(egt2Pin);
		data[0] = egt3 >> 8;
		data[1] = (uint8_t)egt3;
		data[2] = egt4 >> 8;
		data[3] = (uint8_t)egt4;
		HAL_CAN_AddTxMessage(&hcan1, &TxHeader, data, &TxMailbox);
		osDelay(500);
	}
  /* USER CODE END StartEGTTask */
}

void StartShifterTask(void *argument)
{
  /* USER CODE BEGIN StartShifterTask */
	uint16_t rawADCData = 0;
	uint8_t adcGear = 0;
	uint8_t shiftPosition = 0;
  /* Infinite loop */
	for(;;){
		HAL_ADC_Start(&hadc1);
		HAL_ADC_PollForConversion(&hadc1, 200);
		rawADCData = HAL_ADC_GetValue(&hadc1);
		HAL_ADC_Stop(&hadc1);
		if(rawADCData > ADCSHIFTUP){
			if(shiftPosition != 1 && adcGear != 6){
				shiftPosition = 1;
				adcGear ++;
				osMessageQueuePut(shifterQueueHandle, &adcGear, 0, 0);
			}
		}else if(rawADCData < ADCSHIFTDOWN){
			if(shiftPosition != 1 && adcGear != 0){
				shiftPosition = 1;
				adcGear --;
				osMessageQueuePut(shifterQueueHandle, &adcGear, 0, 0);
			}
		}else{
			shiftPosition = 0;
		}
		osDelay(100);
	}
  /* USER CODE END StartShifterTask */
}

void StartGPSTask(void *argument)
{
  /* USER CODE BEGIN StartGPSTask */
	char start[] = "log bestposa ontime 0.1\r\n";
	HAL_UART_Transmit (&huart6, start, sizeof (start), 10);
	HAL_UARTEx_ReceiveToIdle_IT(&huart6, gpsData, UARTBUFFERLENGTH);
	uint8_t currentSector = 3;
	bool lap = false;
	bool sector = false;

	Point currentPoint = { 140, 130 };
	Point lastPoint = { 140, 150 };
	Point startLine1 = { 150, 150 };
	Point startLine2 = { 150, 160 };
	Point sector1EndPoint1 = { 160, 170 };
	Point sector1EndPoint2 = { 160, 180 };
	Point sector2EndPoint1 = { 160, 170 };
	Point sector2EndPoint2 = { 160, 180 };
	osTimerStart(lapTimerHandle, 1);
  /* Infinite loop */
	for(;;){
		if(gpsRecieved){
			currentPoint.x = latitude;
			currentPoint.y = longitude;
			if(currentSector == 3){
				lap = DoIntersect(startLine1, startLine2, currentPoint, lastPoint);
			}else if(currentSector == 2){
				sector = DoIntersect(sector2EndPoint1, sector2EndPoint2, currentPoint, lastPoint);

			}else{
				sector = DoIntersect(sector1EndPoint1, sector1EndPoint2, currentPoint, lastPoint);

			}
			lastPoint = currentPoint;
			transmitCount ++;
			gpsRecieved = false;
		}

		if(lap){
			SendLapTime(lapTimeMilliSeconds);
			lapTimeMilliSeconds = 0;
			lap = false;
		}
		// make function for parsing uart data
		// make function for line intersect function
		osDelay(1);
	}
  /* USER CODE END StartGPSTask */
}

void StartDebounce(void *argument)
{
  /* USER CODE BEGIN StartDebounce */
	uint8_t count = 0;
	uint8_t state = 0;
  /* Infinite loop */
	for(;;){
		state = HAL_GPIO_ReadPin(CHANGE_SCREEN_BUTTON_GPIO_Port, CHANGE_SCREEN_BUTTON_Pin);
		if(state == 0){
			count ++;
		}else{
			count = 0;
		}
		if(count == 5){
			osMessageQueuePut(buttonQueueHandle, &state, 0, 0);
		}
		osDelay(5);
  }
  /* USER CODE END StartDebounce */
}

/* lapTimerCallback function */
void lapTimerCallback(void *argument)
{
  /* USER CODE BEGIN lapTimerCallback */
	lapTimeMilliSeconds ++;
  /* USER CODE END lapTimerCallback */
}
